NS_ :

BS_:

BU_:

BO_ 3 acclerations: 8 17
 SG_ like_acceleration1 : 32|12@1+ (1,0) [0|31] "" XXX
 SG_ like_acceleration2 : 68|12@1+ (1,0) [0|15] "" XXX

BO_ 25 wheel_odo: 8 17
 SG_ NEW_SIGNAL_1 M : 0|1@1+ (1,0) [0|1] "" XXX
 SG_ NEW_SIGNAL_2 m0 : 16|4@1+ (1,0) [0|15] "" XXX
 SG_ wheel_odo1 m0 : 24|16@1+ (1,0) [0|255] "" XXX
 SG_ wheel_odo2 m0 : 48|16@1+ (1,0) [0|511] "" XXX
 SG_ wheel_odo3 m0 : 64|16@1+ (1,0) [0|511] "" XXX
 SG_ wheel_odo4 m0 : 88|16@1+ (1,0) [0|511] "" XXX

BO_ 27 maybe_brake_pressure: 8 17
 SG_ NEW_SIGNAL_2 M : 0|1@1+ (1,0) [0|1] "" XXX
 SG_ NEW_SIGNAL_1 m0 : 24|16@1+ (1,0) [0|255] "" XXX
 SG_ NEW_SIGNAL_3 m0 : 40|16@1+ (1,0) [0|255] "" XXX
 SG_ NEW_SIGNAL_4 m0 : 56|16@1+ (1,0) [0|511] "" XXX
 SG_ NEW_SIGNAL_5 m0 : 72|16@1+ (1,0) [0|511] "" XXX
 SG_ NEW_SIGNAL_6 m0 : 120|4@1+ (1,0) [0|15] "" XXX

BO_ 32 NEW_MSG_20: 8 17
 SG_ NEW_SIGNAL_1 M : 0|1@1+ (1,0) [0|1] "" XXX
 SG_ NEW_SIGNAL_2 m0 : 24|8@1+ (1,0) [0|255] "" XXX
 SG_ NEW_SIGNAL_3 m0 : 32|8@1+ (1,0) [0|7] "" XXX
 SG_ NEW_SIGNAL_4 m0 : 40|8@1+ (1,0) [0|255] "" XXX

BO_ 35 NEW_MSG_23: 8 17

BO_ 38 NEW_MSG_26: 8 17
 SG_ NEW_SIGNAL_2 M : 0|2@1+ (1,0) [0|3] "" XXX
 SG_ NEW_SIGNAL_1 m0 : 24|8@1+ (1,0) [0|255] "" XXX

BO_ 39 NEW_MSG_27: 8 17

BO_ 45 NEW_MSG_2D: 8 17

BO_ 46 wheel_speed: 8 17
 SG_ RL : 24|16@1+ (0.015625,-511.984375) [0|65535] "" XXX
 SG_ RR : 40|16@1+ (0.015625,-511.984375) [0|65535] "" XXX
 SG_ FL : 56|16@1+ (0.015625,-511.984375) [0|65535] "" XXX
 SG_ FR : 72|16@1+ (0.015625,-511.984375) [0|65535] "" XXX

BO_ 49 steer_torque: 8 17
 SG_ cycle_count M : 0|1@0+ (1,0) [0|1] "" XXX
 SG_ driver_steer_torque m0 : 24|12@1+ (0.005,-10) [0|4095] "" XXX

BO_ 51 EPS_Angle: 8 17
 SG_ cycle_count M : 0|1@0+ (1,0) [0|1] "" XXX
 SG_ steering_angle m0 : 24|16@1+ (0.0439453125,-1440) [0|65535] "" XXX

BO_ 53 NEW_MSG_35: 8 17
 SG_ NEW_SIGNAL_1 M : 2|3@0+ (1,0) [0|2047] "" XXX

BO_ 55 vehicle_speed: 8 17
 SG_ cycle_count M : 0|2@1+ (1,0) [0|3] "" XXX
 SG_ acceleration m0 : 24|16@1+ (0.002,-65) [0|65535] "" XXX
 SG_ veh_speed m3 : 24|16@1+ (0.015625,0) [0|65535] "" XXX
 SG_ driving_status m3 : 44|2@1+ (1,0) [0|7] "" XXX

BO_ 56 NEW_MSG_38: 8 17
 SG_ cycle_count M : 0|1@0+ (1,0) [0|3] "" XXX
 SG_ yaw m0 : 24|16@1+ (0.005,-164) [0|255] "" XXX
 SG_ maybe_yaw m0 : 40|16@1+ (0.005,-164) [0|65535] "" XXX

BO_ 58 NEW_MSG_3A: 8 17
 SG_ cycle_count M : 1|2@0+ (1,0) [0|3] "" XXX
 SG_ NEW_SIGNAL_4 m2 : 96|8@1+ (1,0) [0|255] "" XXX
 SG_ NEW_SIGNAL_2 m3 : 52|4@1+ (1,0) [0|255] "" XXX

BO_ 63 seems_all_counters: 8 17
 SG_ NEW_SIGNAL_2 M : 0|2@1+ (1,0) [0|3] "" XXX
 SG_ NEW_SIGNAL_1 m3 : 60|4@1+ (1,0) [0|15] "" XXX

BO_ 68 target_steering_torque: 8 17
 SG_ cycle_count M : 0|1@0+ (1,0) [0|1] "" XXX
 SG_ target_steering_torque m0 : 88|12@1+ (0.005,-10) [0|4095] "" XXX

BO_ 71 NEW_MSG_47: 8 17

BO_ 72 ACC: 8 17
 SG_ cycle_count M : 1|2@0+ (1,0) [0|63] "" XXX
 SG_ crc1 m1 : 8|8@1+ (1,0) [0|255] "" XXX
 SG_ cnt1 m1 : 16|4@1+ (1,0) [0|255] "" XXX
 SG_ always_0x9 m1 : 20|4@1+ (1,0) [0|15] "" XXX
 SG_ steering_angle_req m1 : 24|16@1+ (0.04,-1000) [0|31] "" XXX
 SG_ steer_torque_req m1 : 40|16@1+ (0.006,-196.596) [0|255] "" XXX
 SG_ TJA_ready m1 : 56|8@1+ (1,0) [0|255] "" XXX
 SG_ assist_mode m1 : 64|2@1+ (1,0) [0|1] "" XXX
 SG_ wayback_en1_lane_keeping_trigger m1 : 71|6@0+ (1,0) [0|1] "" XXX
 SG_ lane_keeping_triggered m1 : 72|8@1+ (1,0) [0|255] "" XXX
 SG_ like_assist_torque_reserve m1 : 80|8@1+ (1,0) [0|255] "" XXX
 SG_ constants m1 : 88|26@1+ (1,0) [0|131071] "" XXX
 SG_ wayback_en_2 m1 : 114|2@1+ (1,0) [0|1] "" XXX
 SG_ steering_engaged m1 : 116|4@1+ (1,0) [0|255] "" XXX
 SG_ maybe_assist_force_enhance m1 : 120|8@1+ (1,0) [0|255] "" XXX
 SG_ maybe_assist_force_weaken m1 : 128|8@1+ (1,0) [0|255] "" XXX

BO_ 86 NEW_MSG_56: 8 17
 SG_ NEW_SIGNAL_1 : 32|2@1+ (1,0) [0|3] "" XXX

BO_ 92 NEW_MSG_5C: 8 9
 SG_ NEW_SIGNAL_3 M : 1|2@0+ (1,0) [0|1] "" XXX
 SG_ NEW_SIGNAL_1 m0 : 23|4@0+ (1,0) [0|1] "" XXX
 SG_ NEW_SIGNAL_2 m1 : 16|4@1+ (1,0) [0|15] "" XXX

BO_ 93 NEW_MSG_5D: 8 9
 SG_ NEW_SIGNAL_2 M : 0|2@1+ (1,0) [0|3] "" XXX
 SG_ NEW_SIGNAL_1 m1 : 44|4@1+ (1,0) [0|255] "" XXX
 SG_ NEW_SIGNAL_3 m1 : 50|6@1+ (1,0) [0|3] "" XXX

BO_ 97 NEW_MSG_61: 8 9
 SG_ NEW_SIGNAL_2 M : 1|2@0+ (1,0) [0|3] "" XXX
 SG_ NEW_SIGNAL_1 m1 : 23|4@0+ (1,0) [0|15] "" XXX

BO_ 98 NEW_MSG_62: 8 17

BO_ 100 NEW_MSG_64: 8 9
 SG_ NEW_SIGNAL_1 M : 1|2@0+ (1,0) [0|3] "" XXX
 SG_ NEW_SIGNAL_2 m3 : 23|8@0+ (1,0) [0|255] "" XXX

BO_ 117 NEW_MSG_75: 8 9
 SG_ NEW_SIGNAL_1 M : 0|1@0+ (1,0) [0|3] "" XXX
 SG_ engine_start m0 : 24|4@1+ (1,0) [0|15] "" XXX

BO_ 119 NEW_MSG_77: 8 9

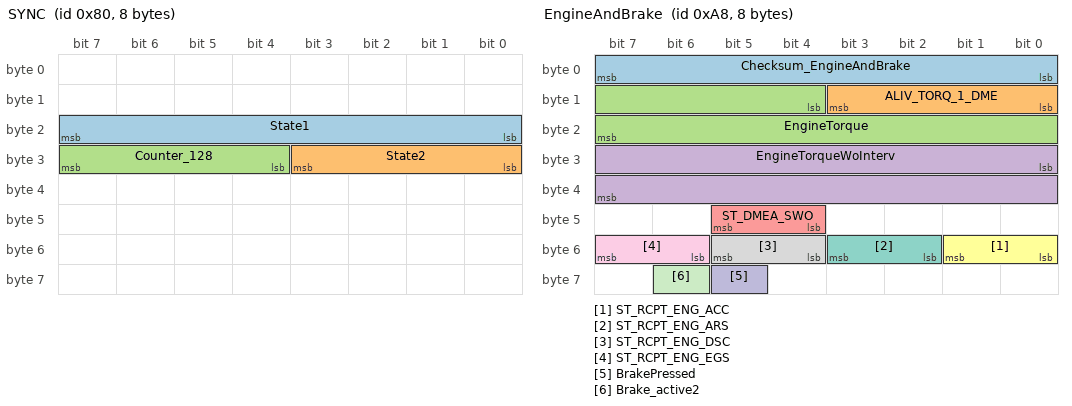
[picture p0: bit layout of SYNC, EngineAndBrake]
BO_ 128 SYNC: 8 5
 SG_ State1 : 16|8@1+ (1,0) [0|255] "" XXX
 SG_ State2 : 24|4@1+ (1,0) [0|15] "" XXX
 SG_ Counter_128 : 28|4@1+ (1,0) [0|15] "" XXX

BO_ 133 Synchronization_SC_VDA: 8 8

BO_ 168 EngineAndBrake: 8 8
 SG_ Checksum_EngineAndBrake : 0|8@1+ (1,0) [0|0] "" XXX
 SG_ ALIV_TORQ_1_DME : 8|4@1+ (1,0) [0|15] "" XXX
 SG_ EngineTorque : 12|12@1- (0.03125,0) [-1024|1023] "" XXX
 SG_ EngineTorqueWoInterv : 24|16@1- (0.03125,0) [-1024|1023.96875] "" XXX
 SG_ ST_DMEA_SWO : 44|2@1+ (1,0) [0|0] "" XXX
 SG_ ST_RCPT_ENG_ACC : 48|2@1+ (1,0) [0|0] "" XXX
 SG_ ST_RCPT_ENG_ARS : 50|2@1+ (1,0) [0|0] "" XXX
 SG_ ST_RCPT_ENG_DSC : 52|2@1+ (1,0) [0|0] "" XXX
 SG_ ST_RCPT_ENG_EGS : 54|2@1+ (1,0) [0|0] "" XXX
 SG_ BrakePressed : 61|1@0+ (1,0) [0|1] "" XXX
 SG_ Brake_active2 : 62|1@0+ (1,0) [0|1] "" XXX

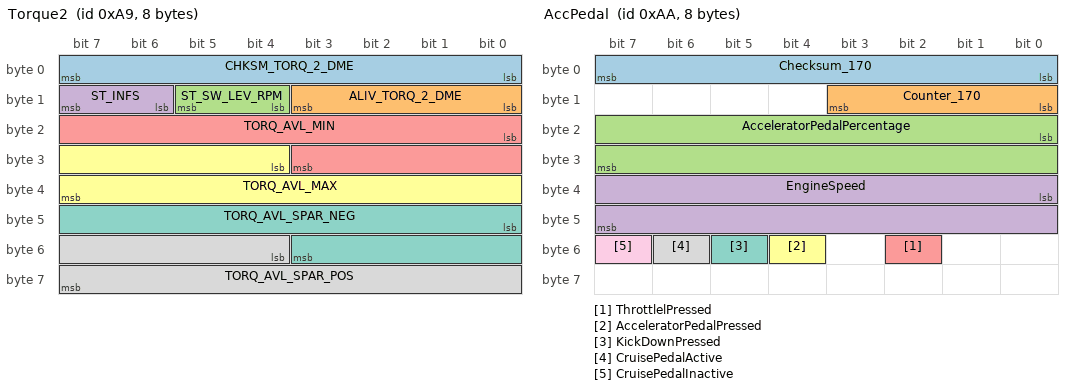
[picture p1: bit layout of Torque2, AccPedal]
BO_ 169 Torque2: 8 8
 SG_ CHKSM_TORQ_2_DME : 0|8@1+ (1,0) [0|0] "" Vector__XXX
 SG_ ALIV_TORQ_2_DME : 8|4@1+ (1,0) [0|0] "" XXX
 SG_ ST_SW_LEV_RPM : 12|2@1+ (1,0) [0|0] "" XXX
 SG_ ST_INFS : 14|2@1+ (1,0) [0|0] "" XXX
 SG_ TORQ_AVL_MIN : 16|12@1- (0.5,0) [-1023.5|1023.5] "Nm" XXX
 SG_ TORQ_AVL_MAX : 28|12@1- (0.5,0) [-1023.5|1023.5] "Nm" XXX
 SG_ TORQ_AVL_SPAR_NEG : 40|12@1- (0.5,0) [-1023.5|1023.5] "Nm" XXX
 SG_ TORQ_AVL_SPAR_POS : 52|12@1- (0.5,0) [-1023.5|1023.5] "Nm" XXX

BO_ 170 AccPedal: 8 8
 SG_ Checksum_170 : 0|8@1- (1,0) [0|65535] "" XXX
 SG_ Counter_170 : 8|4@1+ (1,0) [0|15] "" XXX
 SG_ AcceleratorPedalPercentage : 16|16@1+ (0.04,0) [0|100] "" XXX
 SG_ EngineSpeed : 32|16@1+ (0.25,0) [0|8000] "rpm" XXX
 SG_ ThrottlelPressed : 50|1@0+ (1,0) [0|1] "" XXX
 SG_ AcceleratorPedalPressed : 52|1@0+ (1,0) [0|7] "" XXX
 SG_ KickDownPressed : 53|1@0+ (1,0) [0|3] "" XXX
 SG_ CruisePedalActive : 54|1@0+ (1,0) [0|1] "" XXX
 SG_ CruisePedalInactive : 55|1@0+ (1,0) [0|1] "" XXX

BO_ 172 WheelTorqueDrivetrain2: 8 8

BO_ 177 Torque_request_steering: 8 8

BO_ 181 Torque_request_EGS: 8 8
 SG_ Checksum_Torque_request_EGS : 0|8@1+ (1,0) [0|0] "" XXX
 SG_ Gearbox_temperature : 56|8@1+ (1,0) [0|0] "C" XXX

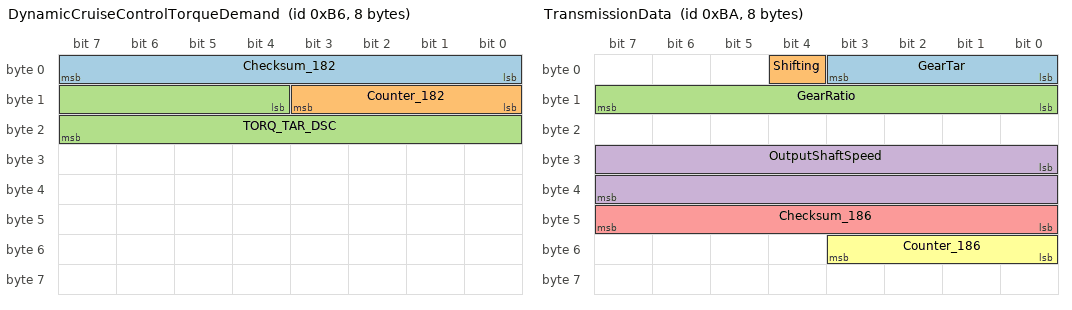
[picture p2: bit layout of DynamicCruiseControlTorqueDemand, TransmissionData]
BO_ 182 DynamicCruiseControlTorqueDemand: 8 8
 SG_ Checksum_182 : 0|8@1+ (1,0) [0|15] "" XXX
 SG_ Counter_182 : 8|4@1+ (1,0) [0|14] "" XXX
 SG_ TORQ_TAR_DSC : 12|12@1- (0.5,0) [0|1000] "" XXX

BO_ 183 Torque_request_ACC: 8 8

BO_ 184 TorqueTransmisionRequest: 8 8
 SG_ Checksum_184 : 0|8@1+ (1,0) [0|15] "" XXX
 SG_ Counter_184 : 8|4@1+ (1,0) [0|15] "" XXX

BO_ 186 TransmissionData: 8 8
 SG_ GearTar : 0|4@1+ (1,-4) [0|255] "" XXX
 SG_ Shifting : 4|1@1+ (1,0) [0|15] "" XXX
 SG_ GearRatio : 8|8@1+ (0.05,0) [0|255] "" XXX
 SG_ OutputShaftSpeed : 24|16@1- (0.125,0) [0|255] "rpm" XXX
 SG_ Checksum_186 : 40|8@1+ (1,0) [0|15] "" XXX
 SG_ Counter_186 : 48|4@1+ (1,0) [0|14] "" XXX

BO_ 187 Target_torque_request: 8 8

BO_ 188 Status_target_torque_conversion: 8 8

BO_ 190 Alive_Counter: 8 8

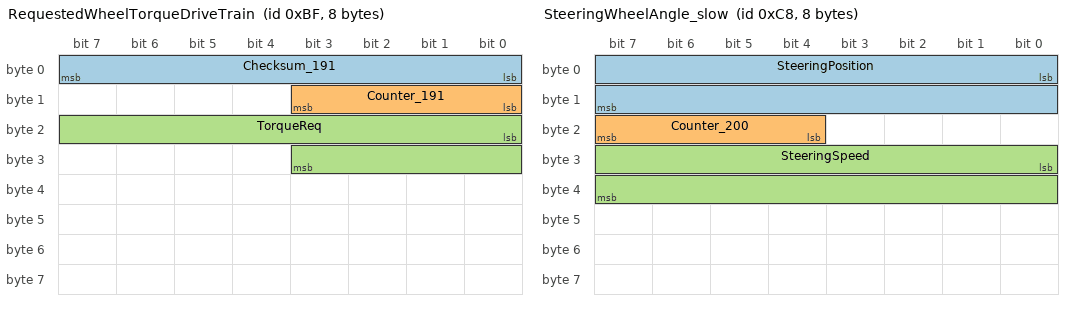
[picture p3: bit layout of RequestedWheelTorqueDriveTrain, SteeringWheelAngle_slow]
BO_ 191 RequestedWheelTorqueDriveTrain: 8 8
 SG_ Checksum_191 : 0|8@1+ (1,0) [0|19] "" XXX
 SG_ Counter_191 : 8|4@1- (1,0) [0|255] "" XXX
 SG_ TorqueReq : 16|12@1- (0.5,350) [-1024|1023.96875] "" XXX

BO_ 193 Alive_counter_telephone: 8 8

BO_ 196 SteeringWheelAngle: 8 7
 SG_ SteeringPosition : 0|16@1- (0.0428316886,0) [-600|600] "degree" XXX
 SG_ SteeringSpeed : 24|16@1- (0.0428316886,0) [0|255] "degree/s" XXX

BO_ 200 SteeringWheelAngle_slow: 8 6
 SG_ SteeringPosition : 0|16@1- (0.0428316886,0) [-600|600] "degree" XXX
 SG_ Counter_200 : 20|4@1+ (1,0) [0|15] "" XXX
 SG_ SteeringSpeed : 24|16@1- (0.0428316886,0) [-65535|65535] "degree/s" XXX

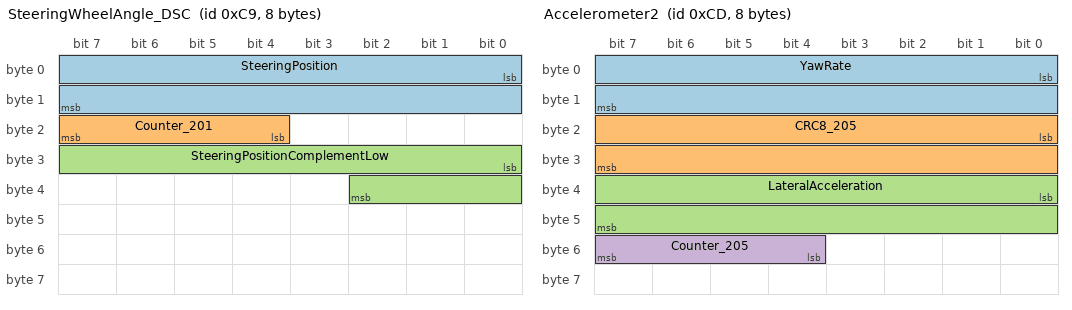
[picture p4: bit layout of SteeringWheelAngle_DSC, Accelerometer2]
BO_ 201 SteeringWheelAngle_DSC: 8 8
 SG_ SteeringPosition : 0|16@1- (0.0428316886,0) [-600|600] "deg" DSC
 SG_ Counter_201 : 20|4@1+ (1,0) [0|15] "" DSC
 SG_ SteeringPositionComplementLow : 24|11@1- (1,0) [0|1] "" DSC

BO_ 205 Accelerometer2: 8 8
 SG_ YawRate : 0|16@1- (1,0) [0|255] "" XXX
 SG_ CRC8_205 : 16|16@1- (1,0) [0|65535] "" XXX
 SG_ LateralAcceleration : 32|16@1- (1,0) [0|255] "" XXX
 SG_ Counter_205 : 52|4@1+ (1,0) [0|255] "" XXX

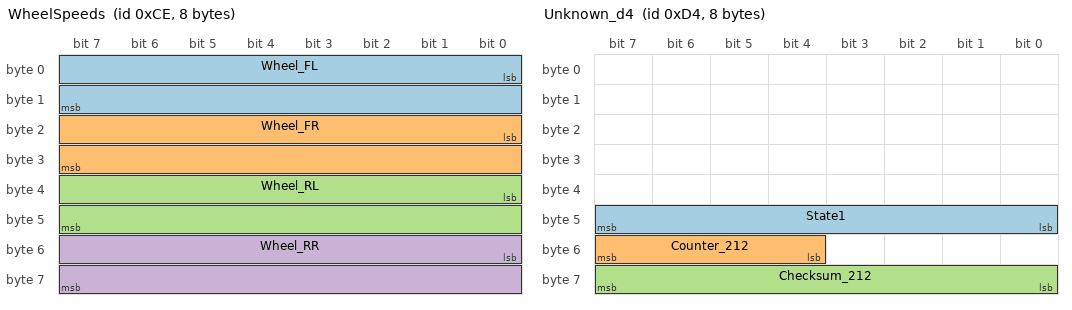
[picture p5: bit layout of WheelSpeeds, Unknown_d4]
BO_ 206 WheelSpeeds: 8 8
 SG_ Wheel_FL : 0|16@1- (0.0625,0) [0|255] "kph" XXX
 SG_ Wheel_FR : 16|16@1- (0.0625,0) [0|255] "kph" XXX
 SG_ Wheel_RL : 32|16@1- (0.0625,0) [0|255] "kph" XXX
 SG_ Wheel_RR : 48|16@1- (0.0625,0) [0|255] "kph" XXX

BO_ 212 Unknown_d4: 8 8
 SG_ State1 : 40|8@1+ (1,0) [0|255] "" XXX
 SG_ Counter_212 : 52|4@1+ (1,0) [0|255] "" XXX
 SG_ Checksum_212 : 56|8@1+ (1,0) [0|255] "" XXX

BO_ 215 Alive_Counter_Security: 8 8

BO_ 216 CLU1_VDA: 8 8

BO_ 217 Acceleration: 8 XXX
 SG_ acccelerator : 16|12@1+ (0.000244,0) [0|2047] "" XXX
 SG_ acceleration : 32|12@1+ (0.000244,0) [0|8191] "" XXX

BO_ 219 Long: 8 XXX
 SG_ NEW_SIGNAL_1 : 32|12@1+ (1,0) [0|65535] "" XXX
 SG_ long_desired : 56|1@0+ (-1,1) [0|1] "" XXX

BO_ 226 Status_central_locking_BFT: 8 8

BO_ 227 CLU2_VDA: 8 8

BO_ 230 Status_central_locking_BFTH: 8 8

BO_ 232 NEW_MSG_E8: 8 9
 SG_ cycle_count M : 1|2@0+ (1,0) [0|3] "" XXX
 SG_ NEW_SIGNAL_1 m2 : 19|1@0+ (1,0) [0|1] "" XXX

BO_ 238 Central_locking_status_FATH: 8 8

BO_ 239 Brake: 8 XXX
 SG_ brake_pedal : 40|12@1+ (-1,3328) [0|3328] "" XXX

BO_ 242 Status_central_locking_HK: 8 8

BO_ 244 CLU3_VDA: 8 8

BO_ 247 lateral_dynamics_ARS_VDM: 8 8

BO_ 249 Vertical_dynamics_VDM_ARS: 8 8

BO_ 250 Control_window_lifter_FAT: 8 8

BO_ 251 Control_window_lifter_BFT: 8 8

BO_ 252 Control_window_lifter_FATH: 8 8

BO_ 253 Control_window_lifter_BFTH: 8 8

BO_ 254 Voltage_level_sensors: 8 8

BO_ 275 NEW_MSG_113: 8 9
 SG_ NEW_SIGNAL_1 M : 2|3@0+ (1,0) [0|7] "" XXX

BO_ 280 Exchange_AFS_DSC: 8 8

BO_ 286 Control_interventions_DSC_AFS: 8 8

BO_ 288 Status_partial_setpoints_AFS_DSC_2: 8 8

BO_ 298 Sensor_data_ROSE: 8 8

BO_ 300 input_data_ROSE: 8 8

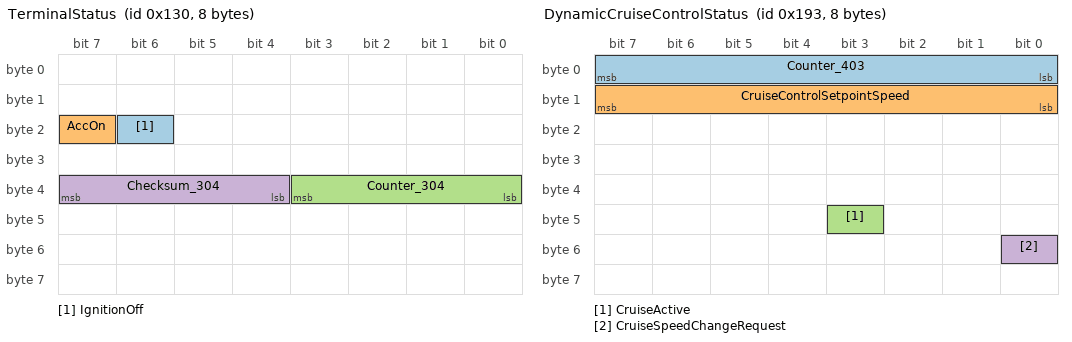
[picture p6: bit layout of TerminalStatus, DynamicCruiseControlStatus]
BO_ 304 TerminalStatus: 8 8
 SG_ IgnitionOff : 22|1@1+ (1,0) [0|3] "" XXX
 SG_ AccOn : 23|1@1+ (1,0) [0|255] "" XXX
 SG_ Counter_304 : 32|4@1+ (1,0) [0|15] "" XXX
 SG_ Checksum_304 : 36|4@1+ (1,0) [0|255] "" XXX

BO_ 309 CrashDisconnectControl: 8 8

BO_ 320 Unknown140: 8 2
 SG_ State : 7|8@0+ (1,0) [0|255] "" XXX

BO_ 336 Request_1_ACC: 8 8

BO_ 339 Request_2_ACC: 8 8

BO_ 341 NEW_MSG_155: 8 XXX
 SG_ NEW_SIGNAL_1 : 32|16@1+ (1,0) [0|65535] "" XXX

BO_ 345 Object_data_ACC: 8 8

BO_ 348 Status_ACC: 8 8

BO_ 351 Requirement_angle_FFP: 8 8

BO_ 357 CLU_Status_VDA: 8 8

BO_ 370 Acknowledgment_request_Kombination: 8 8

BO_ 400 display_ACC: 8 8

BO_ 402 GearSelectorSwitch_1: 8 4
 SG_ Counter_402 : 24|4@1+ (1,0) [0|14] "" XXX

BO_ 403 DynamicCruiseControlStatus: 8 8
 SG_ Counter_403 : 7|8@0+ (1,0) [0|255] "" XXX
 SG_ CruiseControlSetpointSpeed : 15|8@0+ (1,-2) [0|255] "kph/mph" XXX
 SG_ CruiseActive : 43|1@0+ (1,0) [0|1] "" XXX
 SG_ CruiseSpeedChangeRequest : 48|1@0+ (1,0) [0|1] "" XXX

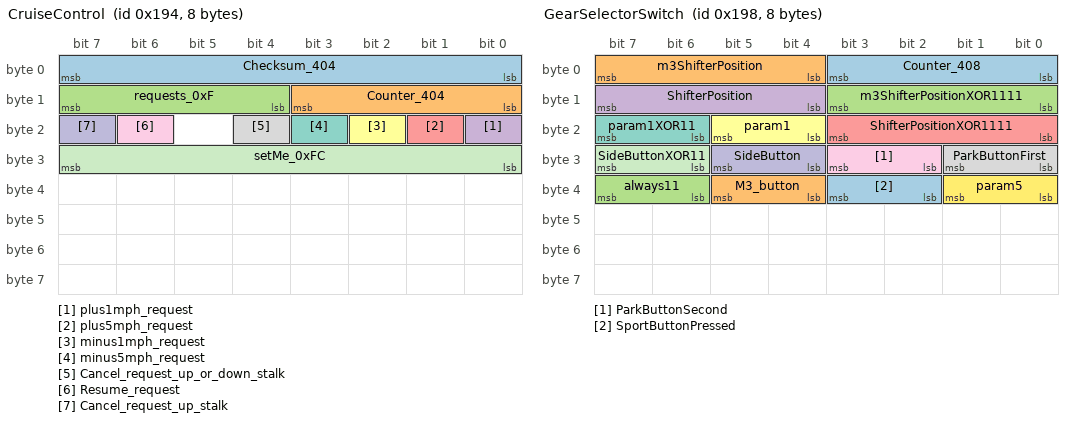
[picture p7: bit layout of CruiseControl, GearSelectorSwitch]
BO_ 404 CruiseControl: 8 4
 SG_ Checksum_404 : 7|8@0+ (1,0) [0|15] "" XXX
 SG_ Counter_404 : 11|4@0+ (1,0) [0|15] "" XXX
 SG_ requests_0xF : 15|4@0+ (1,0) [0|15] "" XXX
 SG_ plus1mph_request : 16|1@0+ (1,0) [0|1] "" XXX
 SG_ plus5mph_request : 17|1@0+ (1,0) [0|0] "" Vector__XXX
 SG_ minus1mph_request : 18|1@0+ (1,0) [0|1] "" XXX
 SG_ minus5mph_request : 19|1@0+ (1,0) [0|0] "" Vector__XXX
 SG_ Cancel_request_up_or_down_stalk : 20|1@0+ (1,0) [0|1] "" XXX
 SG_ Resume_request : 22|1@0+ (1,0) [0|1] "" XXX
 SG_ Cancel_request_up_stalk : 23|1@0+ (1,0) [0|1] "" XXX
 SG_ setMe_0xFC : 31|8@0+ (1,0) [0|255] "" XXX

BO_ 405 Operation_push_button_MSA: 8 8

BO_ 408 GearSelectorSwitch: 8 8
 SG_ Counter_408 : 0|4@1+ (1,0) [0|14] "" XXX
 SG_ m3ShifterPosition : 4|4@1+ (1,0) [0|15] "" XXX
 SG_ m3ShifterPositionXOR1111 : 8|4@1+ (1,0) [0|15] "" XXX
 SG_ ShifterPosition : 12|4@1+ (1,0) [0|0] "" Vector__XXX
 SG_ ShifterPositionXOR1111 : 16|4@1+ (1,0) [0|15] "" XXX
 SG_ param1 : 20|2@1+ (1,0) [0|3] "" XXX
 SG_ param1XOR11 : 22|2@1+ (1,0) [0|3] "" XXX
 SG_ ParkButtonFirst : 24|2@1+ (1,0) [0|3] "" XXX
 SG_ ParkButtonSecond : 26|2@1+ (1,0) [0|3] "" XXX
 SG_ SideButton : 28|2@1+ (1,0) [0|3] "" XXX
 SG_ SideButtonXOR11 : 30|2@1+ (1,0) [0|3] "" XXX
 SG_ param5 : 32|2@1+ (1,0) [0|3] "" XXX
 SG_ SportButtonPressed : 34|2@1+ (1,0) [0|255] "" XXX
 SG_ M3_button : 36|2@1+ (1,0) [0|3] "" XXX
 SG_ always11 : 38|2@1+ (1,0) [0|3] "" XXX

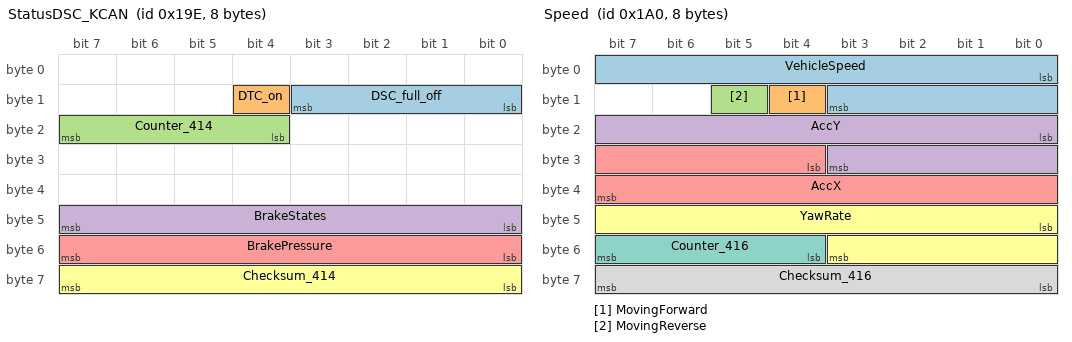
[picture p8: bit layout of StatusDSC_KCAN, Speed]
BO_ 414 StatusDSC_KCAN: 8 8
 SG_ DSC_full_off : 8|4@1+ (1,0) [0|15] "" XXX
 SG_ DTC_on : 12|1@1+ (1,0) [0|3] "" XXX
 SG_ Counter_414 : 20|4@1+ (1,0) [0|15] "" XXX
 SG_ BrakeStates : 40|8@1+ (1,0) [0|255] "" XXX
 SG_ BrakePressure : 48|8@1- (1,0) [0|255] "" XXX
 SG_ Checksum_414 : 56|8@1+ (1,0) [0|15] "" XXX

BO_ 416 Speed: 8 8
 SG_ VehicleSpeed : 0|12@1- (0.103,0) [0|255] "kph" XXX
 SG_ MovingForward : 12|1@1+ (1,0) [0|15] "" XXX
 SG_ MovingReverse : 13|1@1+ (1,0) [0|3] "" XXX
 SG_ AccY : 16|12@1- (1,0) [0|255] "" XXX
 SG_ AccX : 28|12@1- (1,0) [0|15] "" XXX
 SG_ YawRate : 40|12@1- (1,0) [0|255] "" XXX
 SG_ Counter_416 : 52|4@1+ (1,0) [0|14] "" XXX
 SG_ Checksum_416 : 56|8@1+ (1,0) [0|15] "" XXX

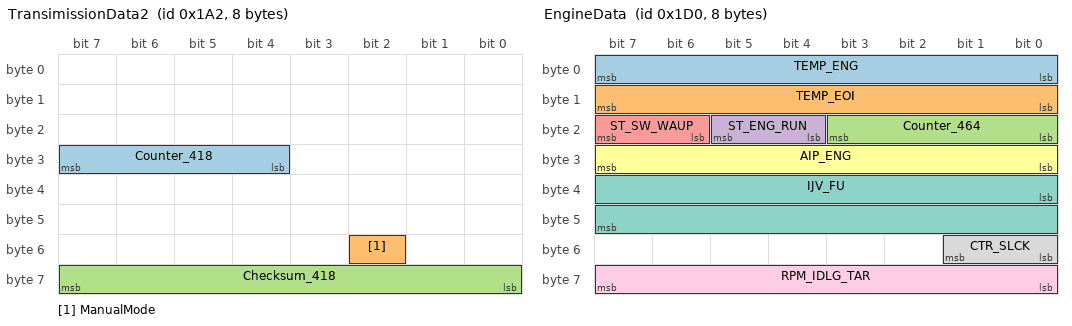
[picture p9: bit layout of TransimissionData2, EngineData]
BO_ 418 TransimissionData2: 8 8
 SG_ Counter_418 : 28|4@1+ (1,0) [0|14] "" XXX
 SG_ ManualMode : 50|1@0+ (1,0) [0|255] "" XXX
 SG_ Checksum_418 : 56|8@1+ (1,0) [0|15] "" XXX

BO_ 419 Raw_data_longitudinal_acceleration: 8 8

BO_ 422 DistanceRoute: 8 8

BO_ 423 actuation_request_EMF: 8 8

BO_ 426 Effect_ErgoCommander: 8 8

BO_ 428 Status_ARS_module: 8 8

BO_ 436 InstrumentClusterStatus_KOMBI: 8 8
 SG_ HandbrakeActive : 41|1@1+ (1,0) [0|3] "" XXX

BO_ 437 HeatFlow_LoadTorqueClimate: 8 8

BO_ 438 HeatFlowEngine: 8 8

BO_ 440 Operation_ErgoCommander: 8 8

BO_ 450 Distance_message_PDC: 8 8

BO_ 464 EngineData: 8 8
 SG_ TEMP_ENG : 0|8@1+ (1,-48) [0|0] "C" XXX
 SG_ TEMP_EOI : 8|8@1+ (1,-48) [0|0] "C" XXX
 SG_ Counter_464 : 16|4@1+ (1,0) [0|14] "" XXX
 SG_ ST_ENG_RUN : 20|2@1+ (1,0) [0|0] "" XXX
 SG_ ST_SW_WAUP : 22|2@1+ (1,0) [0|0] "" XXX
 SG_ AIP_ENG : 24|8@1+ (2,598) [600|1106] "hPa" XXX
 SG_ IJV_FU : 32|16@1+ (1,-48) [0|0] "C" XXX
 SG_ CTR_SLCK : 48|2@1+ (1,0) [0|0] "" XXX
 SG_ RPM_IDLG_TAR : 56|8@1+ (5,0) [0|1270] "1/min" XXX

BO_ 470 SteeringWheel: 3 XXX

BO_ 472 Operation_air_conditioning_air_distribution_FA: 8 8

BO_ 473 Operation_pushbutton_MDrive: 8 8

BO_ 474 Climate_control_remote_control: 8 8

BO_ 476 Operation_stratification_seat_heating: 8 8

BO_ 478 Air_conditioning_controls_rear: 8 8

BO_ 480 Operation_air_conditioning_air_distribution_BF: 8 8

BO_ 482 Operation_air_conditioning_front: 8 8

BO_ 483 Operation_pushbutton_interior_lighting: 8 8

BO_ 487 Operation_seat_heating_seat_climate_FA: 8 8

BO_ 488 Operation_seat_heating_seat_climate_BF: 8 8

BO_ 490 Steering_column_adjustment_control: 8 8

BO_ 491 Operation_active_seat_FA: 8 8

BO_ 492 Operation_active_seat_BF: 8 8

BO_ 499 Operation_seat_memory_FA: 8 8

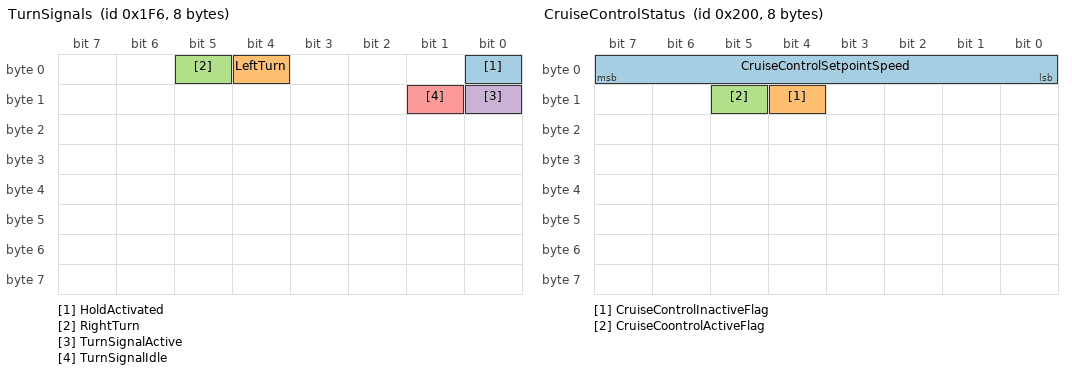
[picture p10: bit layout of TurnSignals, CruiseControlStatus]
BO_ 502 TurnSignals: 8 2
 SG_ HoldActivated : 0|1@1+ (1,0) [0|1] "" XXX
 SG_ LeftTurn : 4|1@1+ (1,0) [0|1] "" XXX
 SG_ RightTurn : 5|1@0+ (1,0) [0|1] "" XXX
 SG_ TurnSignalActive : 8|1@0+ (1,0) [0|1] "" XXX
 SG_ TurnSignalIdle : 9|1@0+ (1,0) [0|1] "" XXX

BO_ 504 Operation_SHD_MDS: 8 8

BO_ 507 Status_EPS: 8 8

BO_ 509 Status_request_EMF_KCAN: 8 8

BO_ 510 Crash: 8 8

BO_ 512 CruiseControlStatus: 8 8
 SG_ CruiseControlSetpointSpeed : 7|8@0+ (0.25,0) [0|255] "mph" XXX
 SG_ CruiseControlInactiveFlag : 12|1@0+ (1,0) [0|1] "" XXX
 SG_ CruiseCoontrolActiveFlag : 13|1@0+ (1,0) [0|1] "" XXX

BO_ 513 Status_EMF_KCAN: 8 8

BO_ 517 Acoustic_request_Kombi: 8 8

BO_ 518 Control_Display_Shiftlights: 8 8

BO_ 523 Memory_adjustment: 8 8

BO_ 524 Steering_column_control: 8 8

BO_ 525 Position_steering_column: 8 8

BO_ 528 Operation_HUD: 8 8

BO_ 529 Status_HUD: 8 8

BO_ 530 Height_levels_air_spring: 8 8

BO_ 538 LampStatus: 8 8

BO_ 540 Operation_NightVision: 8 8

BO_ 542 Status_NightVision: 8 8

BO_ 548 Operation_push_button_NSW: 8 8

BO_ 550 RainSensorWiperSpeed: 8 8

BO_ 552 Operation_special_function: 8 8

BO_ 554 Status_BFS: 8 8

BO_ 556 Operation_push_button_NSL: 8 8

BO_ 558 Status_BFSH: 8 8

BO_ 562 Status_FAS: 8 8

BO_ 566 Status_FASH: 8 8

BO_ 570 Status_radio_key: 8 8

BO_ 571 Status_climate_front_extended: 8 8

BO_ 573 Request_display_climate: 8 8

BO_ 574 Status_Klima_Fond: 8 8

BO_ 578 ClimateFrontStatus: 8 8

BO_ 582 Status_air_conditioning_front_control_unit: 8 8

BO_ 584 Status_rear_view_camera: 8 8

BO_ 585 Control_rear_view_camera: 8 8

BO_ 586 Status_PDC: 8 8

BO_ 587 Status_door_sensors: 8 8

BO_ 594 Wiper_status: 8 8

BO_ 598 Challenge_Passive_Access: 8 8

BO_ 600 Status_Transmission_Passive_Access: 8 8

BO_ 604 Operation_of_climate_additional_programs: 8 8

BO_ 621 Operation_blinds_MK: 8 8

BO_ 622 Control_FH_SHD_central_comfort: 8 8

BO_ 642 Control_security_vehicle_2: 8 8

BO_ 644 Control_remote_start_safety_vehicle: 8 8

BO_ 646 Electrochromic_control: 8 8

BO_ 652 Pushbutton_vertical_dynamics: 8 8

BO_ 653 Operation_pushbutton_sport: 8 8

BO_ 656 Control_response_hydrogen_vehicle: 8 8

BO_ 658 Control_high_beam_assistant: 8 8

BO_ 670 Central_locking_control_for_security_vehicle: 8 8

BO_ 671 Remote_control_FondCommander: 8 8

BO_ 672 Central_locking_control: 8 8

BO_ 674 Operation_of_climate_stand_functions: 8 8

BO_ 676 Operation_personalization: 8 8

BO_ 678 WiperSwitch: 8 8
 SG_ AutoWipersOn : 0|1@1+ (1,0) [0|3] "" XXX

BO_ 690 WheelPressure_KCAN: 8 8

BO_ 691 AccelerationData: 8 8

BO_ 692 DWA_Alarm: 8 8

BO_ 694 Control_horn_DWA: 8 8

BO_ 696 Operation_onboard_computer: 8 8

BO_ 697 Operation_RSE: 8 8

BO_ 698 Stopwatch: 8 8

BO_ 701 Request_switching_display: 8 8

BO_ 702 Switch_status_display: 8 8

BO_ 703 Water_valve_control: 8 8

BO_ 704 LCD_lighting: 8 8

BO_ 705 maybe_gear_switch: 8 17
 SG_ cycle_count M : 0|2@1+ (1,0) [0|3] "" XXX
 SG_ maybe_GEAR m1 : 40|4@1+ (1,0) [0|255] "" XXX
 SG_ GEAR m3 : 24|4@1+ (1,0) [0|255] "" XXX
 SG_ P_locked m3 : 49|1@1+ (1,0) [0|15] "" XXX

BO_ 706 Temperatur_Ist_Fond: 8 8

BO_ 711 Display_Kombination_extended: 8 8

BO_ 716 Control_monitor_rear: 8 8

BO_ 719 Status_of_auxiliary_water_pump: 8 8

BO_ 720 Status_Sensor_AUC: 8 8

BO_ 721 Status_fitting_window_V: 8 8

BO_ 722 Status_pressure_refrigeration_circuit: 8 8

BO_ 723 Status_stratification_rear: 8 8

BO_ 725 Status_heating_rear_window: 8 8

BO_ 726 Status_valve_air_conditioning_compressor: 8 8

BO_ 730 Status_tailgate_lift: 8 8

BO_ 734 Switch_control_display: 8 8

BO_ 738 Status_setting_video_night_vision: 8 8

BO_ 739 Status_setting_video_rear_view_camera: 8 8

BO_ 740 Status_trailer: 8 8

BO_ 742 Status_of_air_distribution_FA: 8 8

BO_ 746 Status_air_distribution_BF: 8 8

BO_ 750 Status_climate_additional_programs: 8 8

BO_ 752 Status_air_condition_functions: 8 8

BO_ 755 Display_switching_instruction: 8 8

BO_ 756 Air_conditioning_control_SH_ZH_auxiliary_water_pump: 8 8

BO_ 758 LightControl: 8 8

BO_ 768 Status_RSE: 8 8

BO_ 773 Operation_button_convertible_top: 8 8

BO_ 774 Vehicle_tilt: 8 8

BO_ 775 Operation_button_flap_convertible_top: 8 8

BO_ 784 AmbientTemperature_RelativeTime: 8 8

BO_ 785 Refill_quantity: 8 8

BO_ 786 Service_Call_Teleservice: 8 8

BO_ 787 Status_Service_Call_Teleservice: 8 8

BO_ 789 Vehicle_mode: 8 8

BO_ 790 OperationPushButtonDTC: 8 2
 SG_ DTC_pressed : 0|1@1+ (1,0) [0|3] "" DSC
 SG_ setMe_0x3FFF : 2|14@1+ (1,0) [0|63] "" DSC

BO_ 791 Operation_button_parking_aids: 8 8

BO_ 792 Status_antennas_Passive_Access: 8 8

BO_ 793 Operation_push_button_RDC: 8 8

BO_ 795 Operation_of_tailgate_interior_button: 8 8

BO_ 796 Status_tire_pressure: 8 8

BO_ 802 Damper_current: 8 8

BO_ 806 Status_damper_program: 8 8

BO_ 813 Display_HDC: 8 8

BO_ 814 Status_climate_internal_control_info: 8 8

BO_ 816 Range_Mileage: 8 8

BO_ 817 Programming_of_step_cruise_control: 8 8

BO_ 818 Driver_display_speed_range: 8 8

BO_ 821 ElectricFuelPumpStatus: 8 8

BO_ 822 Display_check_control_message_role: 8 8

BO_ 824 Control_display_check_control_message: 8 8

BO_ 825 Status_display_climate: 8 8

BO_ 826 Status_Monitor_Front: 8 8

BO_ 828 Status_Monitor_Fond_1: 8 8

BO_ 830 Status_Monitor_Fond_2: 8 8

BO_ 841 Raw_data_level_tank: 8 8

BO_ 843 Seat_back_lock_status_FA: 8 8

BO_ 845 Status_seat_back_lock_BF: 8 8

BO_ 847 Status_contact_handbrake: 8 8
 SG_ Handbrake_push : 0|2@1+ (1,0) [0|3] "" XXX

BO_ 858 Appointment_Condition_Based_Service: 8 8

BO_ 860 Status_onboard_computer: 8 8

BO_ 862 Onboard_computer_data_trip_data: 8 8

BO_ 864 Data_onboard_computer_start_of_journey: 8 8

BO_ 866 Data_onboard_computer_average_values: 8 8

BO_ 868 Data_onboard_computer_arrival: 8 8

BO_ 869 Status_terminal_request: 8 8

BO_ 870 Display_Kombination_external_display: 8 8

BO_ 871 Control_display_of_demand_oriented_service: 8 8

BO_ 877 Setting_the_driving_dynamics_switch: 8 8

BO_ 884 WheelToleranceAdjustment: 8 8

BO_ 893 Status_DKG: 8 8

BO_ 894 Temperatur_Bremse: 8 8

BO_ 895 Range_of_diesel_exhaust_gas_additive: 8 8

BO_ 896 chassis_number: 8 8

BO_ 898 Electronic_engine_oil_dipstick_M: 8 8

BO_ 899 Motor_data_2: 8 8

BO_ 904 Vehicle_type: 8 8

BO_ 907 Status_battery: 8 8

BO_ 910 Start_speed: 8 8

BO_ 914 Status_System_AFS: 8 8

BO_ 916 RDA_request_data_storage: 8 8

BO_ 917 Coding_power_management: 8 8

BO_ 920 Operation_chassis: 8 8

BO_ 921 Status_MDrive: 8 6

BO_ 926 Operation_time_date: 8 8

BO_ 931 Request_Remote_Services: 8 8

BO_ 937 Status_motor_control_CKM: 8 8

BO_ 939 Status_Shiftlights_CKM: 8 8

BO_ 940 RunOnTimeTerminal30: 8 8

BO_ 944 Status_gear_reverse: 8 8

BO_ 945 TransmissionData3: 8 8
 SG_ Checksum_946 : 0|8@1+ (1,0) [0|19] "" XXX
 SG_ Counter_945 : 8|4@1+ (1,0) [0|14] "" XXX

BO_ 947 PowerManagmentConsumptionControl: 8 8

BO_ 948 PowerBatteryVoltage: 8 8
 SG_ BatteryVoltage : 7|24@0+ (0.001,0) [0|65535] "" XXX

BO_ 949 Status_water_valve: 8 8

BO_ 950 Position_window_lifter_FAT: 8 8

BO_ 951 Position_window_lifter_FATH: 8 8

BO_ 952 Position_window_regulator_BFT: 8 8

BO_ 953 Position_window_regulator_BFTH: 8 8

BO_ 954 Position_SHD: 8 8

BO_ 956 Position_window_lifter_security_vehicle: 8 8

BO_ 957 Status_consumer_shutdown: 8 8

BO_ 958 PowerRunningTime: 8 8

BO_ 959 Position_window_rear_window: 8 8

BO_ 960 Configuration_FAS: 8 8

BO_ 961 Configuration_BFS: 8 8

BO_ 964 Status_EDCK_CKM: 8 8

BO_ 967 Access_radio: 8 8

BO_ 968 Operation_push_button_radio: 8 8

BO_ 974 Radio_audio_control_interface_display: 8 8

BO_ 975 Acknowledgment_access_radio_audio_control_interface: 8 8

BO_ 979 Status_solar_sensor: 8 8

BO_ 980 Configuration_of_central_locking_CKM: 8 8

BO_ 981 Status_central_locking_CKM: 8 8

BO_ 982 Configuration_DWA_CKM: 8 8

BO_ 983 Status_DWA_CKM: 8 8

BO_ 984 Configuration_RLS_CKM: 8 8

BO_ 985 Status_RLS_CKM: 8 8

BO_ 986 Configuration_of_memory_positions_CKM: 8 8

BO_ 987 Status_memory_positions_CKM: 8 8

BO_ 988 Configuration_light_CKM: 8 8

BO_ 989 Status_light_CKM: 8 8

BO_ 990 Configuration_Climate_CKM: 8 8

BO_ 991 Status_Klima_CKM: 8 8

BO_ 994 Configuration_of_tailgate_CKM: 8 8

BO_ 995 Status_tailgate_CKM: 8 8

BO_ 996 Configuration_rear_view_camera_CKM: 8 8

BO_ 1152 NetworkManagment1: 8 8

BO_ 1170 NetworkManagment2: 8 8

BO_ 1175 NetworkManagment3: 8 8

BO_ 1176 NetworkManagment4: 8 8

BO_ 1193 NetworkManagment5: 8 8

BO_ 1246 GWS_ShiftLeverHeartbeat: 8 8
 SG_ IgnOff : 12|1@0+ (1,0) [0|3] "" XXX

BO_ 1408 ServicesKGM: 8 8

BO_ 1426 ServicesDME: 8 8

BO_ 1432 ServicesDKG: 8 8

BO_ 1449 ServicesDSC: 8 8

BO_ 1504 ServicesKOMBI: 8 8

BO_ 1522 ServicesKBM: 8 8

BO_ 1577 Unknown_629: 8 8

CM_ SG_ 219 long_desired "If the user requests longitudinal control. False if disabled by steering wheel or accelerator pressed";
CM_ BO_ 470 "Maybe, carried over from E series";
